# R7FA2E2A7 register map
Vendor: Renesas Electronics Corporation; Series: RA2; File version: 1.10.02
CPU: CM23 r1p0, little endian, MPU, no FPU, VTOR, 2 interrupt priority bits, 32 interrupts
Registers are 32-bit, read-write, reset 0x0 unless marked. A register's access mark holds for its fields unless they carry their own. Offsets are from the block's base; [hi:lo] are bit positions; {n}, {i} and the like mark numbered series.

## DOC — Data Operation Circuit
Base 0x40054100
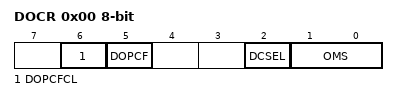
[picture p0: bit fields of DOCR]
0x00 DOCR 8-bit — DOC Control Register
  [6] DOPCFCL — DOPCF Clear
    0=Retain DOPCF flag state; 1=Clear DOPCF flag
  [5] DOPCF ro — DOC Flag
  [2] DCSEL — Detection Condition Select
    0=Set DOPCF flag when data mismatch is detected; 1=Set DOPCF flag when data match is detected
  [1:0] OMS — Operating Mode Select
    0=Data comparison mode; 1=Data addition mode; 2=Data subtraction mode; 3=Setting prohibited
0x02 DODIR 16-bit — DOC Data Input Register
0x04 DODSR 16-bit — DOC Data Setting Register

## CRC — Cyclic Redundancy Check Calculator
Base 0x40074000
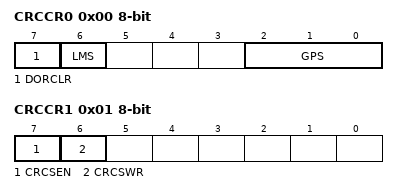
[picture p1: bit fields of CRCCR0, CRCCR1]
0x00 CRCCR0 8-bit — CRC Control Register 0
  [7] DORCLR wo — CRCDOR/CRCDOR_HA/CRCDOR_BY Register Clear
    0=No effect; 1=Clear the CRCDOR/CRCDOR_HA/CRCDOR_BY register
  [6] LMS — CRC Calculation Switching
    0=Generate CRC code for LSB-first communication; 1=Generate CRC code for MSB-first communication
  [2:0] GPS — CRC Generating Polynomial Switching
    1=8-bit CRC-8 (X8 + X2 + X + 1); 2=16-bit CRC-16 (X16 + X15 + X2 + 1); 3=16-bit CRC-CCITT (X16 + X12 + X5 + 1); 4=32-bit CRC-32 (X32 + X26 + X23 + X22 + X16 + X12 + X11 +X10 + X8 + X7 + X5 + X4 + X2 + X + 1); 5=32-bit CRC-32C (X32 + X28 + X27 + X26 + X25 + X23 + X22 + X20 + X19 + X18 + X14 + X13 + X11 + X10 + X9 + X8 + X6 + 1); other=Others (No calculation is executed)
0x01 CRCCR1 8-bit — CRC Control Register 1
  [7] CRCSEN — Snoop Enable
    0=Disabled; 1=Enabled
  [6] CRCSWR — Snoop-On-Write/Read Switch
    0=Snoop-on-read; 1=Snoop-on-write
0x04 CRCDIR — CRC Data Input Register
0x04 CRCDIR_BY 8-bit (alternate view of CRCDIR) — CRC Data Input Register
0x08 CRCDOR — CRC Data Output Register
0x08 CRCDOR_HA 16-bit (alternate view of CRCDOR) — CRC Data Output Register
0x08 CRCDOR_BY 8-bit (alternate view of CRCDOR) — CRC Data Output Register
0x0C CRCSAR 16-bit — Snoop Address Register
  [13:0] CRCSA — Register Snoop Address

## GPT_OPS — Output Phase Switching Controller
Base 0x40078FF0
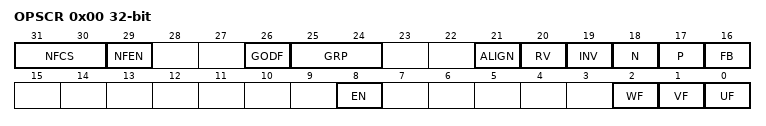
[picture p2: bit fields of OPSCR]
0x00 OPSCR — Output Phase Switching Control Register
  [31:30] NFCS — External Input Noise Filter Clock Selection
    0=PCLKD/1; 1=PCLKD/4; 2=PCLKD/16; 3=PCLKD/64
  [29] NFEN — External Input Noise Filter Enable
    0=Do not use a noise filter on the external input; 1=Use a noise filter on the external input
  [26] GODF — Group Output Disable Function
    0=This bit function is ignored; 1=Group disable clears the OPSCR.EN bit
  [25:24] GRP — Output Disabled Source Selection
  [21] ALIGN — Input Phase Alignment
    0=Input phase aligned to PCLKD; 1=Input phase aligned to the falling edge of PWM
  [20] RV — Output Phase Rotation Direction Reversal Control
    0=Positive rotation; 1=Reverse rotation
  [19] INV — Output Phase Invert Control
    0=Positive logic (active-high) output; 1=Negative logic (active-low) output
  [18] N — Negative-Phase Output (N) Control
    0=Level signal output; 1=PWM signal output
  [17] P — Positive-Phase Output (P) Control
    0=Level signal output; 1=PWM signal output
  [16] FB — External Feedback Signal Enable
    0=Do not use; 1=Select the soft setting (OPSCR.UF, VF, WF)
  [8] EN — Output Phase Enable
    0=Do not output (Hi-Z external pin); 1=Output
  [2] WF
  [1] VF
  [0] UF

## KINT — Key Interrupt Function
Base 0x40080000
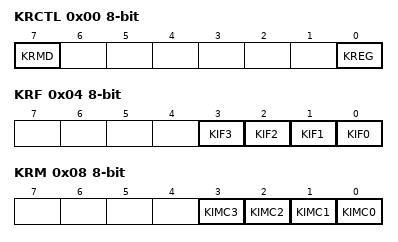
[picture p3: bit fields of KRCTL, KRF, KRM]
0x00 KRCTL 8-bit — Key Return Control Register
  [7] KRMD — Usage of Key Interrupt Flags (KRF.KIF0 to KRF.KIF3)
    0=Do not use key interrupt flags; 1=Use key interrupt flags
  [0] KREG — Detection Edge Selection (KR00 to KR03 pins)
    0=Falling edge; 1=Rising edge
0x04 KRF 8-bit — Key Return Flag Register
  [all] fields
    0=No interrupt detected; 1=Interrupt detected
  [n] KIF{n} (n=0..3) — Key Interrupt Flag n
0x08 KRM 8-bit — Key Return Mode Register
  [all] fields
    0=Do not detect key interrupt signals; 1=Detect key interrupt signals
  [n] KIMC{n} (n=0..3) — Key Interrupt Mode Control n

## AGTW0 — Low Power Asynchronous General Purpose Timer 0
Base 0x40084000
Same registers: AGTW1 0x40084100
0x00 AGT reset 0xFFFFFFFF — AGT Counter Register
0x04 AGTCMA reset 0xFFFFFFFF — AGT CounterCompare Match A Register
0x08 AGTCMB reset 0xFFFFFFFF — AGT CounterCompare Match B Register
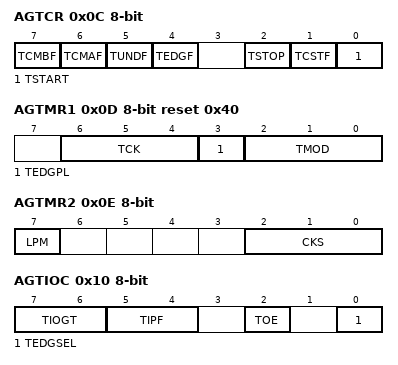
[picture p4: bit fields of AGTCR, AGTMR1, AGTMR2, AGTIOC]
0x0C AGTCR 8-bit — AGT Control Register
  [7] TCMBF — Compare Match B Flag
    0=No match; 1=Match
  [6] TCMAF — Compare Match A Flag
    0=No match; 1=Match
  [5] TUNDF — Underflow Flag
    0=No underflow; 1=Underflow
  [4] TEDGF — Active Edge Judgment Flag
    0=No active edge received; 1=Active edge received
  [2] TSTOP wo — AGT Count Forced Stop
    0=Writing is invalid; 1=The count is forcibly stopped
  [1] TCSTF ro — AGT Count Status Flag
    0=Count stopped; 1=Count in progress
  [0] TSTART — AGT Count Start
    0=Count stops; 1=Count starts
0x0D AGTMR1 8-bit reset 0x40 — AGT Mode Register 1
  [6:4] TCK — Count Source
    0=PCLKB; 1=PCLKB/8; 3=PCLKB/2; 4=Divided clock AGTLCLK specified by CKS[2:0] bits in the AGTMR2 register; 5=Underflow event signal from AGTW0; 6=Setting prohibited; other=Others (Setting prohibited)
  [3] TEDGPL — Edge Polarity
    0=Single-edge; 1=Both-edge
  [2:0] TMOD — Operating Mode
    0=Timer mode; 1=Pulse output mode; 2=Event counter mode; 3=Pulse width measurement mode; 4=Pulse period measurement mode; other=Others (Setting prohibited)
0x0E AGTMR2 8-bit — AGT Mode Register 2
  [7] LPM — Low Power Mode
    0=Normal mode; 1=Low power mode
  [2:0] CKS — AGTLCLK Count Source Clock Frequency Division Ratio
    0=1/1; 1=1/2; 2=1/4; 3=1/8; 4=1/16; 5=1/32; 6=1/64; 7=1/128
0x0F AGTIOSEL 8-bit — AGT Pin Select Register
  [4] TIES — AGTWIOn Pin Input Enable
    0=External event input is disabled during Software Standby mode; 1=External event input is enabled during Software Standby mode
0x10 AGTIOC 8-bit — AGT I/O Control Register
  [7:6] TIOGT — Count Control
    0=Event is always counted; 1=Event is counted during polarity period specified for AGTWEEn pin; other=Others (Setting prohibited)
  [5:4] TIPF — Input Filter
    0=No filter; 1=Filter sampled at PCLKB; 2=Filter sampled at PCLKB/8; 3=Filter sampled at PCLKB/32
  [2] TOE — AGTWOn pin Output Enable
    0=AGTWOn pin output disabled; 1=AGTWOn pin output enabled
  [0] TEDGSEL — I/O Polarity Switch
0x11 AGTISR 8-bit — AGT Event Pin Select Register
  [2] EEPS — AGTWEEn Polarity Selection
    0=An event is counted during the low-level period; 1=An event is counted during the high-level period
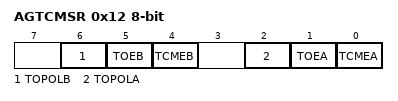
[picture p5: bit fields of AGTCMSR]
0x12 AGTCMSR 8-bit — AGT Compare Match Function Select Register
  [6] TOPOLB — AGTWOBn Pin Polarity Select
    0=AGTWOBn pin output is started on low. i.e. normal output; 1=AGTWOBn pin output is started on high. i.e. inverted output
  [5] TOEB — AGTWOBn Pin Output Enable
    0=AGTWOBn pin output disabled; 1=AGTWOBn pin output enabled
  [4] TCMEB — AGT Compare Match B Register Enable
    0=Compare match B register disabled; 1=Compare match B register enabled
  [2] TOPOLA — AGTWOAn Pin Polarity Select
    0=AGTWOAn pin output is started on low. i.e. normal output; 1=AGTWOAn pin output is started on high. i.e. inverted output
  [1] TOEA — AGTWOAn Pin Output Enable
    0=AGTWOAn pin output disabled; 1=AGTWOAn pin output enabled
  [0] TCMEA — AGT Compare Match A Register Enable
    0=AGT Compare match A register disabled; 1=AGT Compare match A register enabled
